# wl_phy_rxf_secure register map
Vendor: Texas Instruments
Peripheral module from a debugger description file (folder CC35X1E).
Registers are 32-bit, access per field, no defined reset value unless marked. A register's access mark holds for its fields unless they carry their own. Offsets are as the file gives them; lines under a group give offsets from that group; [hi:lo] are bit positions; {n}, {i} and the like mark numbered series; 'fields as' and 'values as' point back to an identical list; <NAME> marks a mode.

## wl_phy_rxf_secure
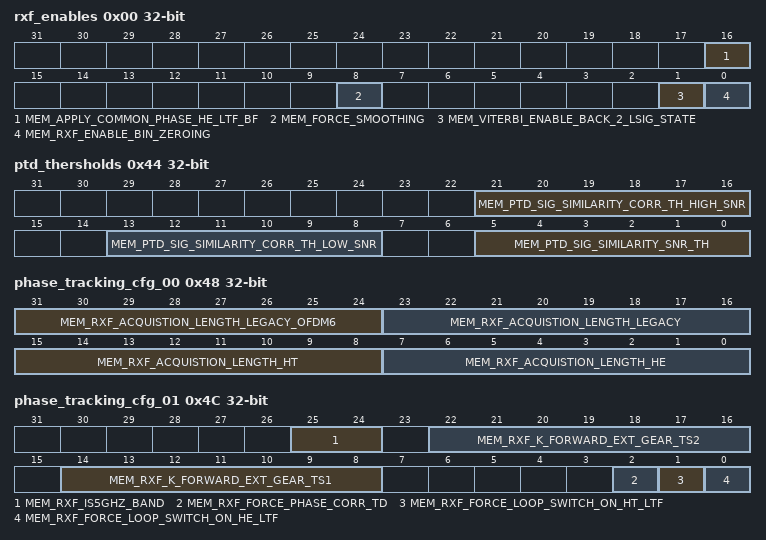
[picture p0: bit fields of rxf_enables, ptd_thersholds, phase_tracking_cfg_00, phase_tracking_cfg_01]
0x00 rxf_enables
  [16] MEM_APPLY_COMMON_PHASE_HE_LTF_BF rw, [8] MEM_FORCE_SMOOTHING rw, [1] MEM_VITERBI_ENABLE_BACK_2_LSIG_STATE rw, [0] MEM_RXF_ENABLE_BIN_ZEROING rw
0x04 viterbi_trace_back_status ro reset 0x0
  [31:0] VITERBI_TRACE_BACK_OUT
0x08 scrambler_init_value_status ro reset 0x0
  [31:0] SCRAMBLER_INIT_VALUE
0x44 ptd_thersholds
  [21:16] MEM_PTD_SIG_SIMILARITY_CORR_TH_HIGH_SNR rw, [13:8] MEM_PTD_SIG_SIMILARITY_CORR_TH_LOW_SNR rw, [5:0] MEM_PTD_SIG_SIMILARITY_SNR_TH rw
0x48 phase_tracking_cfg_00 rw
  [31:24] MEM_RXF_ACQUISTION_LENGTH_LEGACY_OFDM6, [23:16] MEM_RXF_ACQUISTION_LENGTH_LEGACY, [15:8] MEM_RXF_ACQUISTION_LENGTH_HT, [7:0] MEM_RXF_ACQUISTION_LENGTH_HE
0x4C phase_tracking_cfg_01
  [25:24] MEM_RXF_IS5GHZ_BAND rw, [22:16] MEM_RXF_K_FORWARD_EXT_GEAR_TS2 rw, [14:8] MEM_RXF_K_FORWARD_EXT_GEAR_TS1 rw, [2] MEM_RXF_FORCE_PHASE_CORR_TD rw, [1] MEM_RXF_FORCE_LOOP_SWITCH_ON_HT_LTF rw, [0] MEM_RXF_FORCE_LOOP_SWITCH_ON_HE_LTF rw
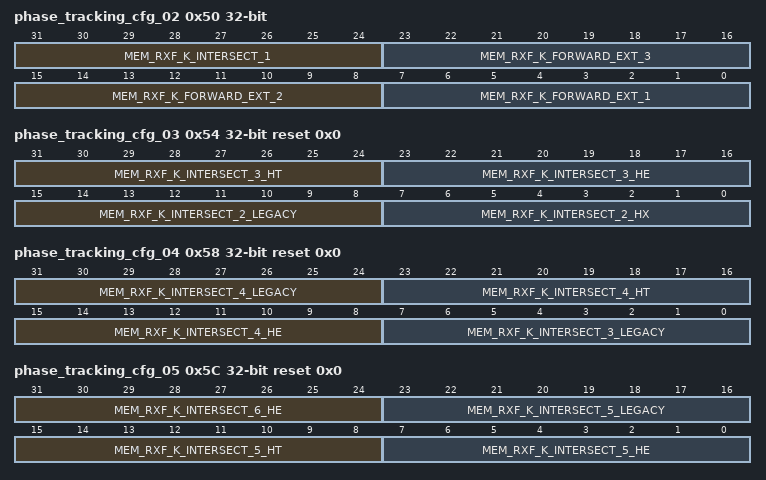
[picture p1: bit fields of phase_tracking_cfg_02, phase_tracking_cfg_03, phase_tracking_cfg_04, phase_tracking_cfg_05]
0x50 phase_tracking_cfg_02 rw
  [31:24] MEM_RXF_K_INTERSECT_1, [23:16] MEM_RXF_K_FORWARD_EXT_3, [15:8] MEM_RXF_K_FORWARD_EXT_2, [7:0] MEM_RXF_K_FORWARD_EXT_1
0x54 phase_tracking_cfg_03 rw reset 0x0
  [31:24] MEM_RXF_K_INTERSECT_3_HT, [23:16] MEM_RXF_K_INTERSECT_3_HE, [15:8] MEM_RXF_K_INTERSECT_2_LEGACY, [7:0] MEM_RXF_K_INTERSECT_2_HX
0x58 phase_tracking_cfg_04 rw reset 0x0
  [31:24] MEM_RXF_K_INTERSECT_4_LEGACY, [23:16] MEM_RXF_K_INTERSECT_4_HT, [15:8] MEM_RXF_K_INTERSECT_4_HE, [7:0] MEM_RXF_K_INTERSECT_3_LEGACY
0x5C phase_tracking_cfg_05 rw reset 0x0
  [31:24] MEM_RXF_K_INTERSECT_6_HE, [23:16] MEM_RXF_K_INTERSECT_5_LEGACY, [15:8] MEM_RXF_K_INTERSECT_5_HT, [7:0] MEM_RXF_K_INTERSECT_5_HE
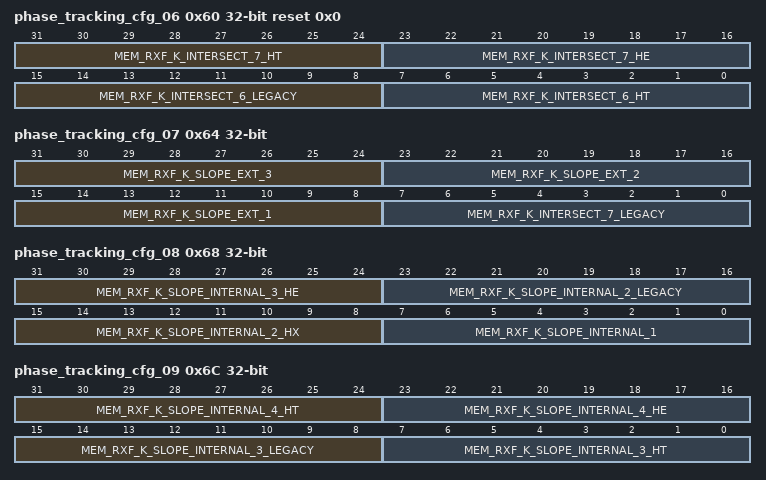
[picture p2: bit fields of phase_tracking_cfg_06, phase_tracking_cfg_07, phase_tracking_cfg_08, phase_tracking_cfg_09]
0x60 phase_tracking_cfg_06 rw reset 0x0
  [31:24] MEM_RXF_K_INTERSECT_7_HT, [23:16] MEM_RXF_K_INTERSECT_7_HE, [15:8] MEM_RXF_K_INTERSECT_6_LEGACY, [7:0] MEM_RXF_K_INTERSECT_6_HT
0x64 phase_tracking_cfg_07 rw
  [31:24] MEM_RXF_K_SLOPE_EXT_3, [23:16] MEM_RXF_K_SLOPE_EXT_2, [15:8] MEM_RXF_K_SLOPE_EXT_1, [7:0] MEM_RXF_K_INTERSECT_7_LEGACY
0x68 phase_tracking_cfg_08 rw
  [31:24] MEM_RXF_K_SLOPE_INTERNAL_3_HE, [23:16] MEM_RXF_K_SLOPE_INTERNAL_2_LEGACY, [15:8] MEM_RXF_K_SLOPE_INTERNAL_2_HX, [7:0] MEM_RXF_K_SLOPE_INTERNAL_1
0x6C phase_tracking_cfg_09 rw
  [31:24] MEM_RXF_K_SLOPE_INTERNAL_4_HT, [23:16] MEM_RXF_K_SLOPE_INTERNAL_4_HE, [15:8] MEM_RXF_K_SLOPE_INTERNAL_3_LEGACY, [7:0] MEM_RXF_K_SLOPE_INTERNAL_3_HT
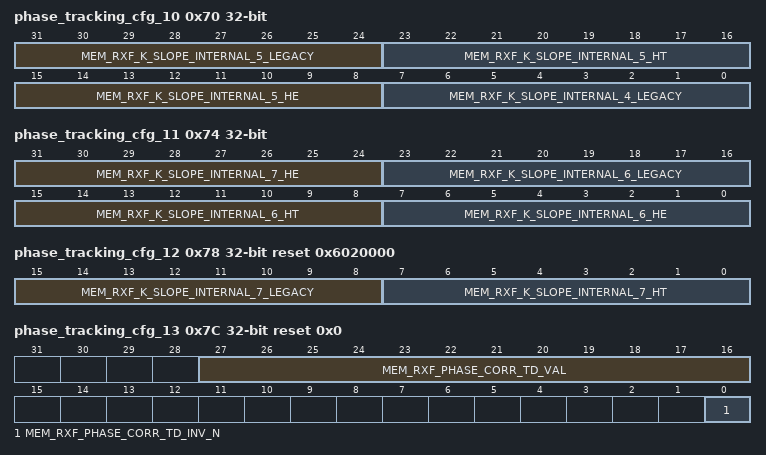
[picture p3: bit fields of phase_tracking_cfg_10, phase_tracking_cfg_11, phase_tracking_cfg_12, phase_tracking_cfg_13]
0x70 phase_tracking_cfg_10 rw
  [31:24] MEM_RXF_K_SLOPE_INTERNAL_5_LEGACY, [23:16] MEM_RXF_K_SLOPE_INTERNAL_5_HT, [15:8] MEM_RXF_K_SLOPE_INTERNAL_5_HE, [7:0] MEM_RXF_K_SLOPE_INTERNAL_4_LEGACY
0x74 phase_tracking_cfg_11 rw
  [31:24] MEM_RXF_K_SLOPE_INTERNAL_7_HE, [23:16] MEM_RXF_K_SLOPE_INTERNAL_6_LEGACY, [15:8] MEM_RXF_K_SLOPE_INTERNAL_6_HT, [7:0] MEM_RXF_K_SLOPE_INTERNAL_6_HE
0x78 phase_tracking_cfg_12 reset 0x6020000 (reset mask 0xFFFF0000)
  [15:8] MEM_RXF_K_SLOPE_INTERNAL_7_LEGACY rw, [7:0] MEM_RXF_K_SLOPE_INTERNAL_7_HT rw
0x7C phase_tracking_cfg_13 reset 0x0
  [27:16] MEM_RXF_PHASE_CORR_TD_VAL rw, [0] MEM_RXF_PHASE_CORR_TD_INV_N rw
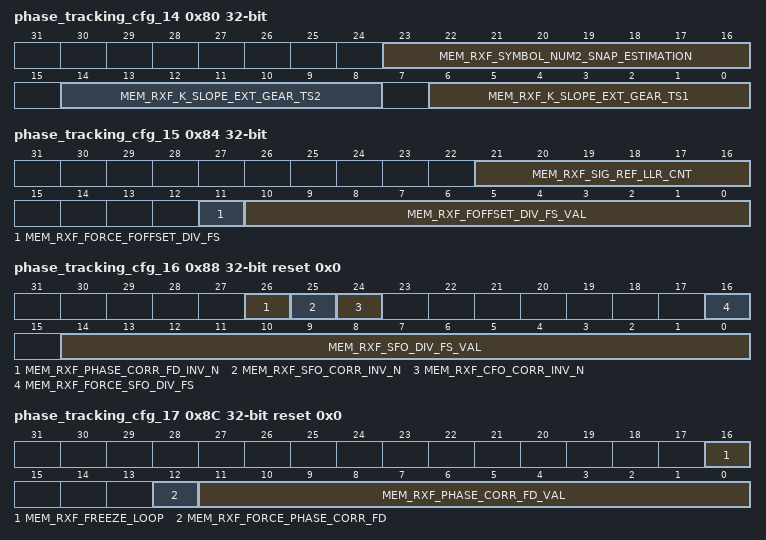
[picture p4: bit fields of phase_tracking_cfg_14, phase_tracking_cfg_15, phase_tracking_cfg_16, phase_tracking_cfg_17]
0x80 phase_tracking_cfg_14
  [23:16] MEM_RXF_SYMBOL_NUM2_SNAP_ESTIMATION rw, [14:8] MEM_RXF_K_SLOPE_EXT_GEAR_TS2 rw, [6:0] MEM_RXF_K_SLOPE_EXT_GEAR_TS1 rw
0x84 phase_tracking_cfg_15
  [21:16] MEM_RXF_SIG_REF_LLR_CNT rw, [11] MEM_RXF_FORCE_FOFFSET_DIV_FS rw, [10:0] MEM_RXF_FOFFSET_DIV_FS_VAL rw
0x88 phase_tracking_cfg_16 reset 0x0
  [26] MEM_RXF_PHASE_CORR_FD_INV_N rw, [25] MEM_RXF_SFO_CORR_INV_N rw, [24] MEM_RXF_CFO_CORR_INV_N rw, [16] MEM_RXF_FORCE_SFO_DIV_FS rw, [14:0] MEM_RXF_SFO_DIV_FS_VAL rw
0x8C phase_tracking_cfg_17 reset 0x0
  [16] MEM_RXF_FREEZE_LOOP rw, [12] MEM_RXF_FORCE_PHASE_CORR_FD rw, [11:0] MEM_RXF_PHASE_CORR_FD_VAL rw
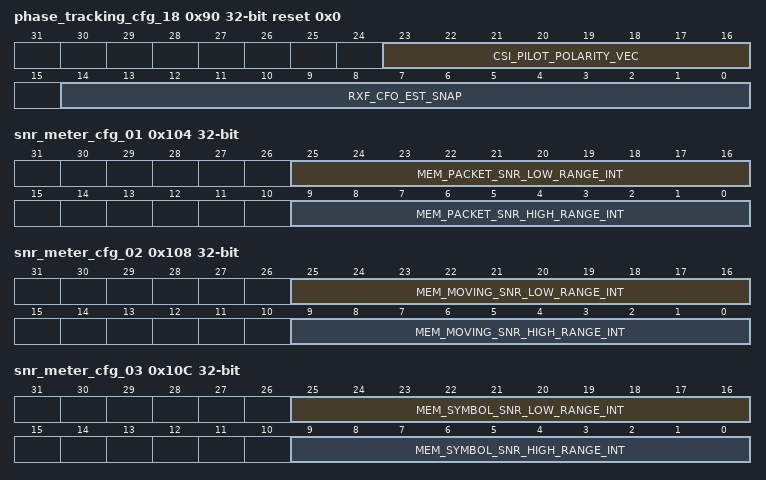
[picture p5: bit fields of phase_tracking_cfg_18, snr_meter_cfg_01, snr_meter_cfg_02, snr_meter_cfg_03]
0x90 phase_tracking_cfg_18 ro reset 0x0
  [23:16] CSI_PILOT_POLARITY_VEC, [14:0] RXF_CFO_EST_SNAP
0x100 snr_meter_cfg_00 reset 0x24 — Rx SnrMeter configuration reg
  [2:0] MEM_MOVING_AVERAGE_ALPHA rw — The forgetting factor of the moving average SNR estimation.
0x104 snr_meter_cfg_01 — Rx SnrMeter configuration reg
  [25:16] MEM_PACKET_SNR_LOW_RANGE_INT rw — If packet SNR is lower than PacketSNRLowRangeInt, PacketSNRInt is raised.
  [9:0] MEM_PACKET_SNR_HIGH_RANGE_INT rw — If packet SNR is bigger than PacketSNRHighRangeInt, PacketSNRInt is raised.
0x108 snr_meter_cfg_02 — Rx SnrMeter configuration reg
  [25:16] MEM_MOVING_SNR_LOW_RANGE_INT rw — If moving SNR is lower than MovingSNRLowRangeInt, MovingSNRInt is raised.
  [9:0] MEM_MOVING_SNR_HIGH_RANGE_INT rw — If moving SNR is bigger than MovingSNRHighRangeInt, MovingSNRInt is raised.
0x10C snr_meter_cfg_03 — Rx SnrMeter configuration reg
  [25:16] MEM_SYMBOL_SNR_LOW_RANGE_INT rw — If Symbol SNR is lower than SymbolSNRLowRangeInt, SymbolSNRInt is raised.
  [9:0] MEM_SYMBOL_SNR_HIGH_RANGE_INT rw — If Symbol SNR is bigger than SymbolSNRHighRangeInt, SymbolSNRInt is raised.
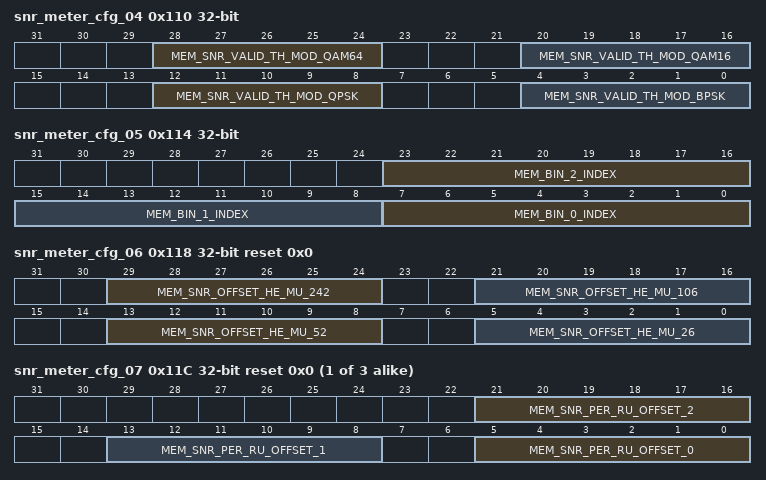
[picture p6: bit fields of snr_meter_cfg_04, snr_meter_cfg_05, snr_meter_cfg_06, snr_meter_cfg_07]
0x110 snr_meter_cfg_04 — Rx SnrMeter configuration reg
  [28:24] MEM_SNR_VALID_TH_MOD_QAM64 rw — If modulation is QAM64 and measured packet SNR is less than SNRValidThModQAM64, SNRValidFlag is false.
  [20:16] MEM_SNR_VALID_TH_MOD_QAM16 rw — If modulation is QAM16 and measured packet SNR is less than SNRValidThModBQAM16, SNRValidFlag is false.
  [12:8] MEM_SNR_VALID_TH_MOD_QPSK rw — If modulation is QPSK and measured packet SNR is less than SNRValidThModQPSK, SNRValidFlag is false.
  [4:0] MEM_SNR_VALID_TH_MOD_BPSK rw — If modulation is BPSK and measured packet SNR is less than SNRValidThModBPSK, SNRValidFlag is false.
0x114 snr_meter_cfg_05 — Rx SnrMeter configuration reg
  [23:16] MEM_BIN_2_INDEX rw — SNRBin2 status register index. The indexes are in HE notations. Non He indexes should be written with 2 LSB zeros (Only 6 MSBs are valid for non-He packets).
  [15:8] MEM_BIN_1_INDEX rw — SNRBin1 status register index. The indexes are in HE notations. Non He indexes should be written with 2 LSB zeros (Only 6 MSBs are valid for non-He packets).
  [7:0] MEM_BIN_0_INDEX rw — SNRBin0 status register index. The indexes are in HE notations. Non He indexes should be written with 2 LSB zeros (Only 6 MSBs are valid for non-He packets).
0x118 snr_meter_cfg_06 reset 0x0 — Rx SnrMeter configuration reg
  [29:24] MEM_SNR_OFFSET_HE_MU_242 rw — The Viterbi llr scaling uses active RU SNR estimation. We might like to shift this measured value by SNROffsetHeMU_XX dB when HE_MU packet with RU size XX
  [21:16] MEM_SNR_OFFSET_HE_MU_106 rw — The Viterbi llr scaling uses active RU SNR estimation. We might like to shift this measured value by SNROffsetHeMU_XX dB when HE_MU packet with RU size XX
  [13:8] MEM_SNR_OFFSET_HE_MU_52 rw — The Viterbi llr scaling uses active RU SNR estimation. We might like to shift this measured value by SNROffsetHeMU_XX dB when HE_MU packet with RU size XX
  [5:0] MEM_SNR_OFFSET_HE_MU_26 rw — The Viterbi llr scaling uses active RU SNR estimation. We might like to shift this measured value by SNROffsetHeMU_XX dB when HE_MU packet with RU size XX
{0x100+4i} snr_meter_cfg_{i:02} reset 0x0 (i=7..9) — Rx SnrMeter configuration reg
  [21:16] MEM_SNR_PER_RU_OFFSET_{3i-19} rw — The SNR per RU estimation might be erroneous due to non-accounted for spurs/wiped bin. This might degrade SNR estimation performance. These registers allow compensating for these impairments.
  [13:8] MEM_SNR_PER_RU_OFFSET_{3i-20} rw — The SNR per RU estimation might be erroneous due to non-accounted for spurs/wiped bin. This might degrade SNR estimation performance. These registers allow compensating for these impairments.
  [5:0] MEM_SNR_PER_RU_OFFSET_{3i-21} rw — The SNR per RU estimation might be erroneous due to non-accounted for spurs/wiped bin. This might degrade SNR estimation performance. These registers allow compensating for these impairments.
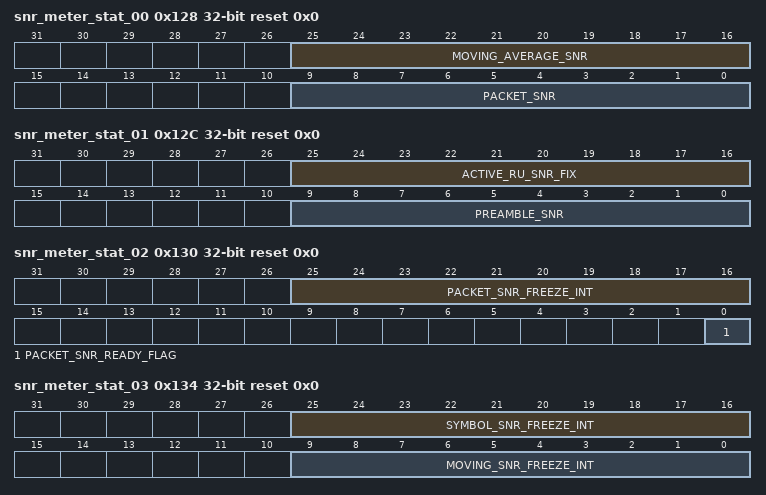
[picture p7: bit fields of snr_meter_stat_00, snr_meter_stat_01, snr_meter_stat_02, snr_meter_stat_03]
0x128 snr_meter_stat_00 ro reset 0x0 — Rx SnrMeter status reg
  [25:16] MOVING_AVERAGE_SNR — average snr
  [9:0] PACKET_SNR — snr per packet
0x12C snr_meter_stat_01 ro reset 0x0 — Rx SnrMeter status reg
  [25:16] ACTIVE_RU_SNR_FIX — snr for active RU
  [9:0] PREAMBLE_SNR — snr preamble
0x130 snr_meter_stat_02 ro reset 0x0 — Rx SnrMeter status reg
  [25:16] PACKET_SNR_FREEZE_INT — The value of the Packet SNR when PacketSNRInt set high.
  [0] PACKET_SNR_READY_FLAG — Set to high every update of Packet SNR.
0x134 snr_meter_stat_03 ro reset 0x0 — Rx SnrMeter status reg
  [25:16] SYMBOL_SNR_FREEZE_INT — The value of the SymbolSNR when SymbolSNRInt set high.
  [9:0] MOVING_SNR_FREEZE_INT — The value of the MovingAverageSNR when MovingSNRInt set high.
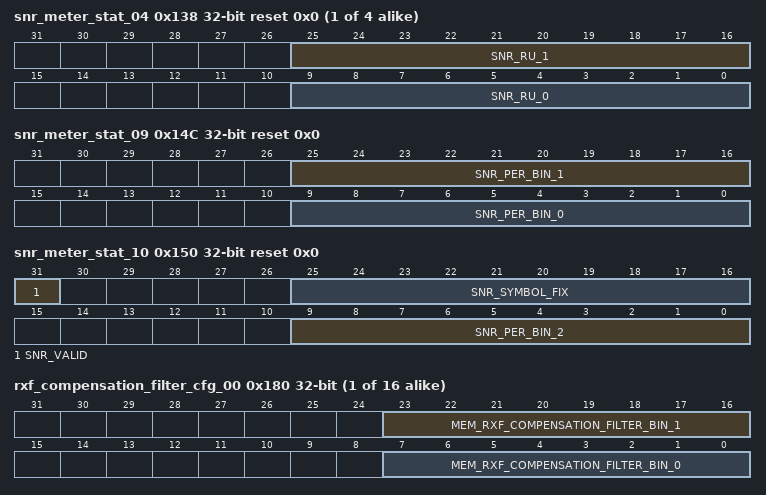
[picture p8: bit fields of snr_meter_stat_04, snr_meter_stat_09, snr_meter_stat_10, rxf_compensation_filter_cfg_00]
{0x128+4i} snr_meter_stat_{i:02} ro reset 0x0 (i=4..7) — Rx SnrMeter status reg
  [25:16] SNR_RU_{2i-7} — snr for ru {2i-7}
  [9:0] SNR_RU_{2i-8} — snr for ru {2i-8}
0x148 snr_meter_stat_08 ro reset 0x0 — Rx SnrMeter status reg
  [9:0] SNR_RU_8 — snr for ru 8
0x14C snr_meter_stat_09 ro reset 0x0 — Rx SnrMeter status reg
  [25:16] SNR_PER_BIN_1 — snr for bin 1
  [9:0] SNR_PER_BIN_0 — snr for bin 0
0x150 snr_meter_stat_10 ro reset 0x0 — Rx SnrMeter status reg
  [31] SNR_VALID — snr for bin 2
  [25:16] SNR_SYMBOL_FIX — snr for bin 2
  [9:0] SNR_PER_BIN_2 — snr for bin 2
{0x180+4i} rxf_compensation_filter_cfg_{i:02} (i=0..15)
  [23:16] MEM_RXF_COMPENSATION_FILTER_BIN_{2i+1} rw — Compensation Filter configuable values
  [7:0] MEM_RXF_COMPENSATION_FILTER_BIN_{2i} rw — Compensation Filter configuable values
0x1C0 rxf_compensation_filter_cfg_16 reset 0x1010
  [7:0] MEM_RXF_COMPENSATION_FILTER_BIN_32 rw — Compensation Filter configuable values
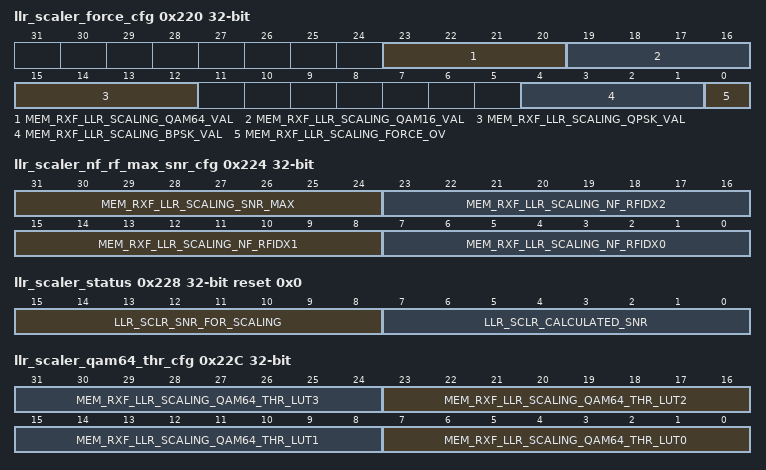
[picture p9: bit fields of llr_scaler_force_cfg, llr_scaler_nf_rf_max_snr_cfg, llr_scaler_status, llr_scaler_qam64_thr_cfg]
0x220 llr_scaler_force_cfg — LLR Scaler register used for using of forced values for scalers
  [23:20] MEM_RXF_LLR_SCALING_QAM64_VAL rw — In force mode, used as fixed scaling.
  [19:16] MEM_RXF_LLR_SCALING_QAM16_VAL rw — In force mode, used as fixed scaling.
  [15:12] MEM_RXF_LLR_SCALING_QPSK_VAL rw — In force mode, used as fixed scaling.
  [4:1] MEM_RXF_LLR_SCALING_BPSK_VAL rw — In force mode, used as fixed scaling.
  [0] MEM_RXF_LLR_SCALING_FORCE_OV rw — Force the scaler to the ones in the scaling registers
0x224 llr_scaler_nf_rf_max_snr_cfg rw — LLR Scaler Noise Figures and Max Calculated SNR configuration
  [31:24] MEM_RXF_LLR_SCALING_SNR_MAX — Max Value for Calculated SNR [dB]
  [23:16] MEM_RXF_LLR_SCALING_NF_RFIDX2 — Noise figure for RF index 2 Default --> 7.5 x 2^3 = 60 [dB]
  [15:8] MEM_RXF_LLR_SCALING_NF_RFIDX1 — Noise figure for RF index 1 Default --> 5.375 x 2^3 = 43 [dB]
  [7:0] MEM_RXF_LLR_SCALING_NF_RFIDX0 — Noise figure for RF index 0 [dB]
0x228 llr_scaler_status ro reset 0x0 — Status register for LLR Scaler
  [15:8] LLR_SCLR_SNR_FOR_SCALING — The SNR used for scaling. It is updated according to SnrSymbolCounter value. [dB]
  [7:0] LLR_SCLR_CALCULATED_SNR — Calculated SNR - Changes only in LSIG or MRC LSIG/RLSIG [dB]
0x22C llr_scaler_qam64_thr_cfg rw — LLR Scaler register for QAM64 Scaler Threshold configuraton
  [8n+7:8n] MEM_RXF_LLR_SCALING_QAM64_THR_LUT{n} (n=0..3) — QAM64 Scaler Threshold LUT[{n}] [dB]
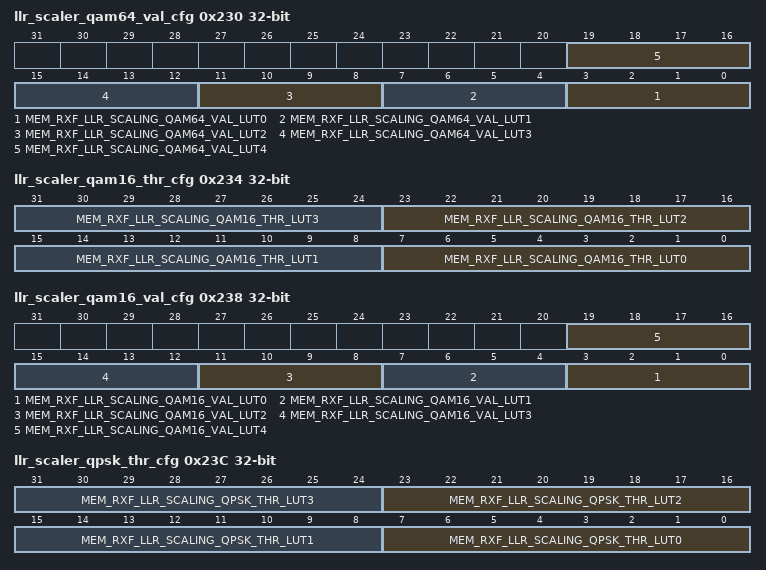
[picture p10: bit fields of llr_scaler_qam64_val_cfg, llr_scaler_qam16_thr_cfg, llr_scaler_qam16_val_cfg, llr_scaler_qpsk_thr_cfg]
0x230 llr_scaler_qam64_val_cfg — LLR Scaler register for QAM64 Scaler Value configuraton
  [4n+3:4n] MEM_RXF_LLR_SCALING_QAM64_VAL_LUT{n} rw (n=0..4) — QAM64 Scaler Value LUT[{n}]
0x234 llr_scaler_qam16_thr_cfg rw — LLR Scaler register for QAM16 Scaler Threshold configuraton
  [8n+7:8n] MEM_RXF_LLR_SCALING_QAM16_THR_LUT{n} (n=0..3) — QAM16 Scaler Threshold LUT[{n}] [dB]
0x238 llr_scaler_qam16_val_cfg — LLR Scaler register for QAM16 Scaler Value configuraton
  [4n+3:4n] MEM_RXF_LLR_SCALING_QAM16_VAL_LUT{n} rw (n=0..4) — QAM16 Scaler Value LUT[{n}]
0x23C llr_scaler_qpsk_thr_cfg rw — LLR Scaler register for QPSK Scaler Threshold configuraton
  [8n+7:8n] MEM_RXF_LLR_SCALING_QPSK_THR_LUT{n} (n=0..3) — QPSK Scaler Threshold LUT[{n}] [dB]
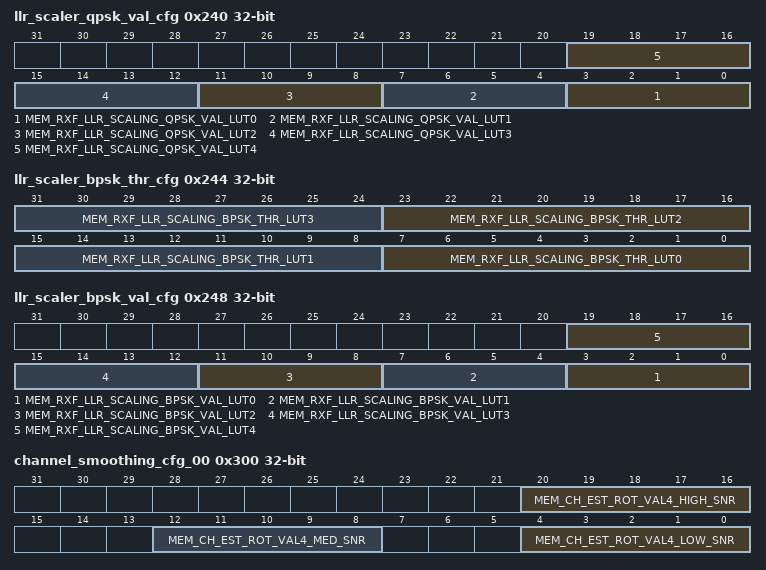
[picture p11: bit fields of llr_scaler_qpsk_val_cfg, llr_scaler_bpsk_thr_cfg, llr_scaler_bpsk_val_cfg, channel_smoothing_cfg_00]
0x240 llr_scaler_qpsk_val_cfg — LLR Scaler register for QPSK Scaler Value configuraton
  [4n+3:4n] MEM_RXF_LLR_SCALING_QPSK_VAL_LUT{n} rw (n=0..4) — QPSK Scaler Value LUT[{n}]
0x244 llr_scaler_bpsk_thr_cfg rw — LLR Scaler register for BPSK Scaler Threshold configuraton
  [8n+7:8n] MEM_RXF_LLR_SCALING_BPSK_THR_LUT{n} (n=0..3) — BPSK Scaler Threshold LUT[{n}] [dB]
0x248 llr_scaler_bpsk_val_cfg — LLR Scaler register for BPSK Scaler Value configuraton
  [4n+3:4n] MEM_RXF_LLR_SCALING_BPSK_VAL_LUT{n} rw (n=0..4) — BPSK Scaler Value LUT[{n}]
0x24C llr_scaler_target_bo_cfg reset 0x71C — LLR Scaler register for Active RU target BO
  [5:0] MEM_RXF_LLR_SCALING_ACTIVE_RU_TARGET_BO rw — The target BO (in dB) of active RU. This target BO is identical to all RUs. It should match full spectrum BO.
0x300 channel_smoothing_cfg_00 — Channel Estimation Rotator value in RSSIs. Units: [Number of Bins]
  [20:16] MEM_CH_EST_ROT_VAL4_HIGH_SNR rw — Above (ChEstSnrIndThrHighPlus110 - 110) dBm
  [12:8] MEM_CH_EST_ROT_VAL4_MED_SNR rw — Between (ChEstSnrIndThrLowPlus110 - 110) dBm and (ChEstSnrIndThrHighPlus110 - 110) dBm
  [4:0] MEM_CH_EST_ROT_VAL4_LOW_SNR rw — Below (ChEstSnrIndThrLowPlus110 - 110) dBm
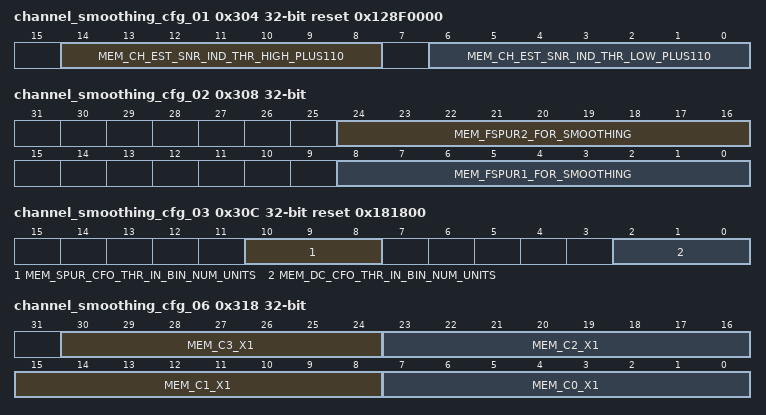
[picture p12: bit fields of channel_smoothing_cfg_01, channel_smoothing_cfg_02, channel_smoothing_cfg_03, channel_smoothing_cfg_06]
0x304 channel_smoothing_cfg_01 reset 0x128F0000 (reset mask 0xFFFF8000) — RSSI Threshold. Units: [dBm + 110]
  [14:8] MEM_CH_EST_SNR_IND_THR_HIGH_PLUS110 rw — High RSSI Threshold
  [6:0] MEM_CH_EST_SNR_IND_THR_LOW_PLUS110 rw — Low RSSI Threshold
0x308 channel_smoothing_cfg_02 — Spur frequency. Units: [Legacy LTF bin num units]
  [24:16] MEM_FSPUR2_FOR_SMOOTHING rw — Spur 2 Frequency
  [8:0] MEM_FSPUR1_FOR_SMOOTHING rw — Spur 1 Frequency
0x30C channel_smoothing_cfg_03 reset 0x181800 (reset mask 0xFFFFF800) — CFO Threshold. Units: [Bin index units (HE or non-HE)]
  [10:8] MEM_SPUR_CFO_THR_IN_BIN_NUM_UNITS rw — DC CFO Threshold
  [2:0] MEM_DC_CFO_THR_IN_BIN_NUM_UNITS rw — Spur CFO Threshold
0x310 channel_smoothing_cfg_04 reset 0x1B36 — NBI Smoothing RSSI Threshold. Units: [dBm + 110]
  [6:0] MEM_NBI_SMOOTHING_RSSI_THR_PLUS110 rw — NBI Smoothing RSSI Threshold
0x314 channel_smoothing_cfg_05 reset 0x0 — Enable Dynamic Raw on edges
  [0] MEM_EN_USE_RAW_ON_EDGES rw
0x318 channel_smoothing_cfg_06 — Filter coefficient for HE LTF X1 - Decimated by 4
  [30:24] MEM_C3_X1 rw — Filter coefficient for HE LTF X1 - Three taps from the center
  [23:16] MEM_C2_X1 rw — Filter coefficient for HE LTF X1 - Two taps from the center
  [15:8] MEM_C1_X1 rw — Filter coefficient for HE LTF X1 - Adjacent to center
  [7:0] MEM_C0_X1 rw — Filter coefficient for HE LTF X1 - Center
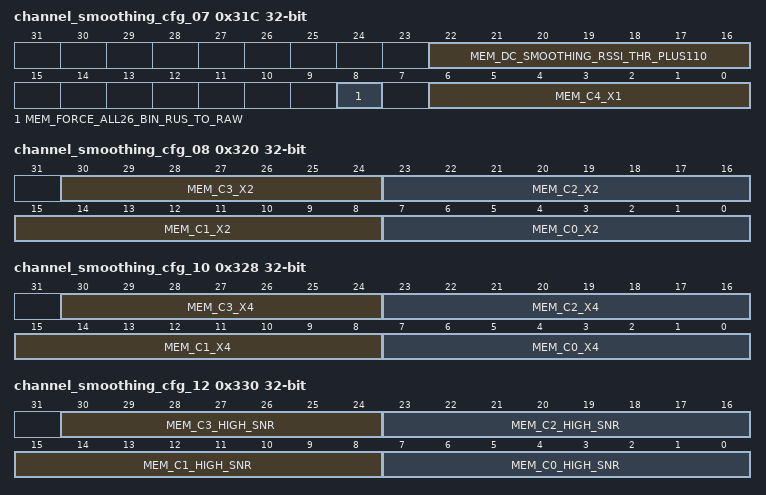
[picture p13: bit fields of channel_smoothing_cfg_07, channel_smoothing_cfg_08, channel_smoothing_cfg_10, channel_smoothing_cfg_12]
0x31C channel_smoothing_cfg_07 — Filter coefficient for HE LTF X1 - Decimated by 4
  [22:16] MEM_DC_SMOOTHING_RSSI_THR_PLUS110 rw
  [8] MEM_FORCE_ALL26_BIN_RUS_TO_RAW rw
  [6:0] MEM_C4_X1 rw — Filter coefficient for HE LTF X1 - Four taps from the center
0x320 channel_smoothing_cfg_08 — Filter coefficient for HE LTF X2 - Decimated by 2
  [30:24] MEM_C3_X2 rw — Filter coefficient for HE LTF X2 - Three taps from the center
  [23:16] MEM_C2_X2 rw — Filter coefficient for HE LTF X2 - Two taps from the center
  [15:8] MEM_C1_X2 rw — Filter coefficient for HE LTF X2 - Adjacent to center
  [7:0] MEM_C0_X2 rw — Filter coefficient for HE LTF X2 - Center
0x324 channel_smoothing_cfg_09 reset 0x3F7E — Filter coefficient for HE LTF X2 - Decimated by 2
  [6:0] MEM_C4_X2 rw — Filter coefficient for HE LTF X2 - Four taps from the center
0x328 channel_smoothing_cfg_10 — Filter coefficient for HE LTF X4 - Decimated by 1 - No decimation
  [30:24] MEM_C3_X4 rw — Filter coefficient for HE LTF X4 - Three taps from the center
  [23:16] MEM_C2_X4 rw — Filter coefficient for HE LTF X4 - Two taps from the center
  [15:8] MEM_C1_X4 rw — Filter coefficient for HE LTF X4 - Adjacent to center
  [7:0] MEM_C0_X4 rw — Filter coefficient for HE LTF X4 - Center
0x32C channel_smoothing_cfg_11 reset 0x102 — Filter coefficient for HE LTF X4 - Decimated by 1 - No decimation
  [6:0] MEM_C4_X4 rw — Filter coefficient for HE LTF X4 - Four taps from the center
0x330 channel_smoothing_cfg_12 — Filter coefficient for non-HE LTF at high SNR
  [30:24] MEM_C3_HIGH_SNR rw — Filter coefficient for non-HE LTF at high RSSI - Three taps from the center
  [23:16] MEM_C2_HIGH_SNR rw — Filter coefficient for non-HE LTF at high RSSI - Two taps from the center
  [15:8] MEM_C1_HIGH_SNR rw — Filter coefficient for non-HE LTF at high RSSI - Adjacent to center
  [7:0] MEM_C0_HIGH_SNR rw — Filter coefficient for non-HE LTF at high RSSI - Center
0x334 channel_smoothing_cfg_13 reset 0x3A74 — Filter coefficient for non-HE LTF at high SNR
  [6:0] MEM_C4_HIGH_SNR rw — Filter coefficient for non-HE LTF at high RSSI - Four taps from the center
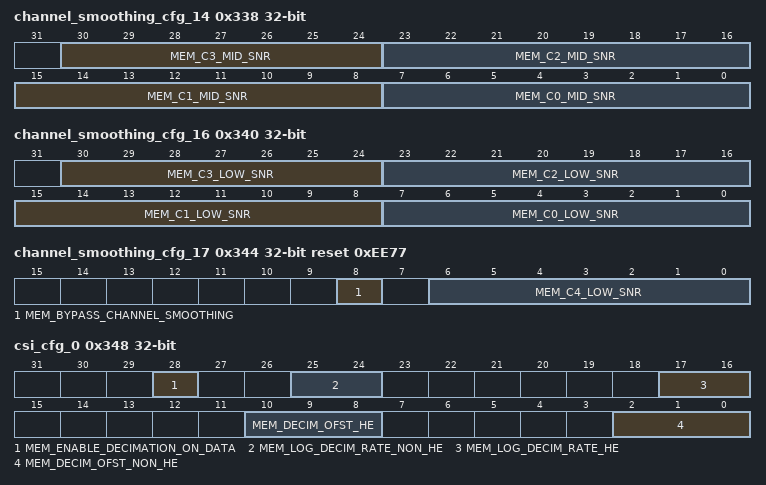
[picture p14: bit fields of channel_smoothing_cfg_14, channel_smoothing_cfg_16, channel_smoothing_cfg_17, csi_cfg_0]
0x338 channel_smoothing_cfg_14 — Filter coefficient for non-HE LTF at mid SNR
  [30:24] MEM_C3_MID_SNR rw — Filter coefficient for non-HE LTF at mid RSSI - Three taps from the center
  [23:16] MEM_C2_MID_SNR rw — Filter coefficient for non-HE LTF at mid RSSI - Two taps from the center
  [15:8] MEM_C1_MID_SNR rw — Filter coefficient for non-HE LTF at mid RSSI - Adjacent to center
  [7:0] MEM_C0_MID_SNR rw — Filter coefficient for non-HE LTF at mid RSSI - Center
0x33C channel_smoothing_cfg_15 reset 0x3A74 — Filter coefficient for non-HE LTF at mid SNR
  [6:0] MEM_C4_MID_SNR rw — Filter coefficient for non-HE LTF at mid RSSI - Four taps from the center
0x340 channel_smoothing_cfg_16 — Filter coefficient for non-HE LTF at low SNR
  [30:24] MEM_C3_LOW_SNR rw — Filter coefficient for non-HE LTF at low RSSI - Three taps from the center
  [23:16] MEM_C2_LOW_SNR rw — Filter coefficient for non-HE LTF at low RSSI - Two taps from the center
  [15:8] MEM_C1_LOW_SNR rw — Filter coefficient for non-HE LTF at low RSSI - Adjacent to center
  [7:0] MEM_C0_LOW_SNR rw — Filter coefficient for non-HE LTF at low RSSI - Center
0x344 channel_smoothing_cfg_17 reset 0xEE77 (reset mask 0xFFFFFE7F) — Filter coefficient for non-HE LTF at low SNR
  [8] MEM_BYPASS_CHANNEL_SMOOTHING rw — Bypass channel smoothing
  [6:0] MEM_C4_LOW_SNR rw — Filter coefficient for non-HE LTF at low RSSI - Four taps from the center
0x348 csi_cfg_0
  [28] MEM_ENABLE_DECIMATION_ON_DATA rw — Enable decimation on data symbols
  [25:24] MEM_LOG_DECIM_RATE_NON_HE rw — Log of decimation rate used on Legacy/HT/VHT CSIs Note that during CSI-Expansion states (i.e. states in which CSI is generated from data and not from an LTF) this register is used, even if packet is HE/EHT. In that case the value of the register may be changed by FW during any RXF-CSI-FSM state which is not a channel-estimation state or DataProcess state. 0 is No decimation 1 is decimation by 2 2 is decimation by 4 3 is decimation by 8
  [17:16] MEM_LOG_DECIM_RATE_HE rw — Log of decimation rate used on HE/EHT CSIs Note that during CSI-Expansion states (i.e. states in which CSI is generated from data and not from an LTF) this register is never used, even if packet is HE/EHT. 0 is No decimation 1 is decimation by 2 2 is decimation by 4 3 is decimation by 8
  [10:8] MEM_DECIM_OFST_HE rw — Decimation offset used for HE/EHT CSI's. Note that during CSI-Expansion states (i.e. states in which CSI is generated from data and not from an LTF) this register is never used, even if packet is HE/EHT. Should be between 0 and (2 power LogDecimRateHe)-1
  [2:0] MEM_DECIM_OFST_NON_HE rw — Log of decimation rate used on HE/EHT CSIs Note that during CSI-Expansion states (i.e. states in which CSI is generated from data and not from an LTF) this register is never used, even if packet is HE/EHT. 0 is No decimation 1 is decimation by 2 2 is decimation by 4 3 is decimation by 8
0x34C csi_cfg_1
  [24] MEM_CSI_FSM_TO_IDLE_IF_MEMORY_IS_LOCKED rw — Disable CSI feature
  [16] MEM_DISABLE_CSI rw — Disable CSI feature
  [9:8] MEM_CSI_PRE_SCALER rw — This sets the number of left-shifts performed on the HVal before it is quantized into CSIs {8,8} bits. Allows to tune the CSIs dynamic range. The higher the number in the reg, the smaller the dynamic range is and the smaller the quantization noise it.
  [6:0] MEM_BF_REPORT_RAM_ADDR_BASE_NON_LEGACY rw — This is the BF-Report-RAM base address for non-legacy-CSI Note that this is used also for CSI-Expansion modes, even if they are based on legacy packets. Also note that the BfReportRamAddBaseLegacy, used for the legacy CSI, is set at 0, and not exported as a register.
0x350 csi_cfg_2 reset 0x0
  [24] CSI_SWITCH_TRASIENT_DONE_WRCL wo — Marks to the CSI-FSM that the AFE/DFE transient immediately following the ant/freq switch, as seen in the TdAcq input, is over. Note that the HW shall automatically add the necessary delays to this in order to make sure next CSI is generated from a non-corrupt symbol.
  [16] CSI_SWITCH_FREQ_WRCL wo — Marks to the CSI-FSM that the AFE/DFE transient immediately following the ant/freq switch, as seen in the TdAcq input, is over. Note that the HW shall automatically add the necessary delays to this in order to make sure next CSI is generated from a non-corrupt symbol.
  [8] CSI_SWITCH_ANT_WRCL wo — Initiates a CSI-Expansion of Antenna-switching type. Note that actual switching of the antenna needs to be configured through
  [0] CSI_RESET_WRCL wo — Resets CSI to IDLE state
0x354 csi_fsm_status ro reset 0x0
  [3:0] csi_fsm_state — CSI_FSM_IDLE = 4'd0, CSI_FSM_LEG_LTF_CH_EST = 4'd1, CSI_FSM_POST_LEGACY = 4'd2, CSI_FSM_HT_LTF_CH_EST = 4'd3, CSI_FSM_HE_LTF_CH_EST = 4'd4, CSI_FSM_POST_TH_OR_HE_LTF = 4'd5, CSI_FSM_WAIT_FOR_TRANSIENT_POST_FREQ_SWITCH = 4'd6, CSI_FSM_WAIT_FOR_TRANSIENT_POST_ANT_SWITCH = 4'd7, CSI_FSM_WAIT_FOR_DATA_READY_POST_FREQ_SWITCH = 4'd8, CSI_FSM_WAIT_FOR_DATA_READY_POST_ANT_SWITCH = 4'd9, CSI_FSM_POST_FREQ_SWITCH_DATA_PROCESS = 4'd10, CSI_FSM_POST_ANT_SWITCH_DATA_PROCESS = 4'd11, CSI_FSM_POST_FREQ_SWITCH_POST_DATA_PROCESS = 4'd12, CSI_FSM_POST_ANT_SWITCH_POST_DATA_PROCESS = 4'd13;
0x370 bf_reset reset 0x0
  [0] BF_RESET_WRCL wo
0x374 bf_memory_status ro reset 0x0
  [1:0] BF_MEMORY_STATUS — 2'b00: BF_RAM_IS_EMPTY 2'b01: BF_RAM_IS_FILLED_WITH_BF_DATA 2'b10: BF_RAM_IS_FILLED_WITH_CSI_DATA 2'b11: BF_RAM_IS_FILLED_WITH_NDP_CSI_DATA
0x378 bf_memory_cobfig reset 0x0
  [0] MEM_PHY_BF_MEMORY_STATUS_RESET_FW_WRCL wo
0x37C bf_report_ram_len_status ro reset 0x0
  [9:0] BF_REPORT_RAM_LENGTH
0x400 bf_report_ram rw reset 0x0
  [31:0] MEM_BF_REPORT_RAM_5FC_WRMEMP — BF Report RAM
